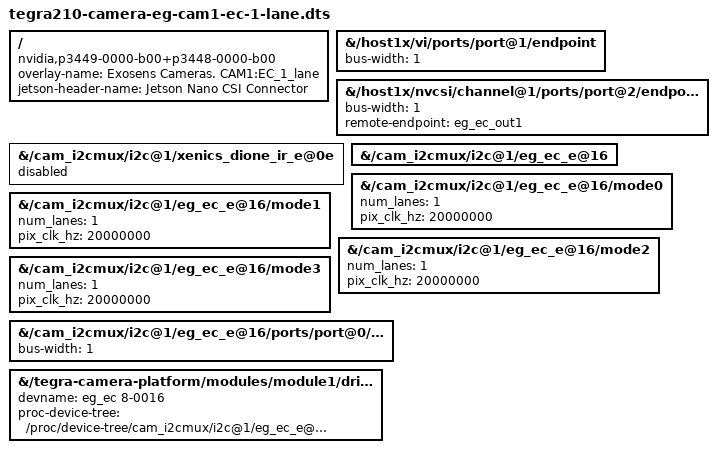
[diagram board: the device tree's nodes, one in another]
// SPDX-License-Identifier: GPL-2.0-only


/dts-v1/;
/plugin/;

/ {
	overlay-name = "Exosens Cameras. CAM1:EC_1_lane";
	jetson-header-name = "Jetson Nano CSI Connector";
	compatible = "nvidia,p3449-0000-b00+p3448-0000-b00", "nvidia,p3449-0000-b00+p3448-0002-b00";

	fragment@10 {
		target-path = "/host1x/vi/ports/port@1/endpoint";
		__overlay__ {
			bus-width=<1>;
		};
	};

	fragment@11 {
		target-path = "/host1x/nvcsi/channel@1/ports/port@2/endpoint@2";
		__overlay__ {
			bus-width=<1>;
         remote-endpoint = <&eg_ec_out1>;
		};
	};

   // Disable Dione cameras
	fragment@12 {
		target-path = "/cam_i2cmux/i2c@1/xenics_dione_ir_e@0e";
		__overlay__ {
         status = "disabled";
		};
	};

   // Enable EngineCore cameras
	fragment@13 {
		target-path = "/cam_i2cmux/i2c@1/eg_ec_e@16";
		__overlay__ {
         status = "okay";
		};
	};
	fragment@14 {   
		target-path = "/cam_i2cmux/i2c@1/eg_ec_e@16/mode0";
		__overlay__ {
         num_lanes = "1";
         pix_clk_hz = "20000000";
		};
	};
	fragment@15 {
		target-path = "/cam_i2cmux/i2c@1/eg_ec_e@16/mode1";
		__overlay__ {
         num_lanes = "1";
         pix_clk_hz = "20000000";
		};
	};
	fragment@16 {
		target-path = "/cam_i2cmux/i2c@1/eg_ec_e@16/mode2";
		__overlay__ {
         num_lanes = "1";
         pix_clk_hz = "20000000";
		};
	};
	fragment@17 {
		target-path = "/cam_i2cmux/i2c@1/eg_ec_e@16/mode3";
		__overlay__ {
         num_lanes = "1";
         pix_clk_hz = "20000000";
		};
	};
	fragment@20 {
		target-path = "/cam_i2cmux/i2c@1/eg_ec_e@16/ports/port@0/endpoint";
		__overlay__ {
			bus-width=<1>;
		};
	};

	fragment@21 {
		target-path = "/tegra-camera-platform/modules/module1/drivernode0";
		__overlay__ {
         devname = "eg_ec 8-0016";
			proc-device-tree = "/proc/device-tree/cam_i2cmux/i2c@1/eg_ec_e@16";
		};
	};


};
